AUTOSAR XML (schema 4-2-2)
package /ComponentTypes
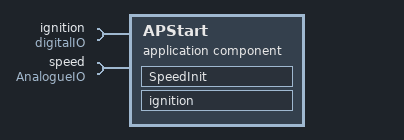
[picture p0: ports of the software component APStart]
  application sw component type APStart
    require port ignition: nonqueued-receiver-com-spec{data-element=boolean, init-value=0}, required-interface=digitalIO
    require port speed: nonqueued-receiver-com-spec{data-element=speed, init-value=0}, required-interface=AnalogueIO
    behavior APStart_InternalBehavior: data-type-mapping=speedMapSet
      init event SpeedPoll_InitEvent: start-on-event=SpeedInit
      init event ignition_InitEvent: start-on-event=ignition
      port-api-options:
        enable-take-address=true, error-handling=NO-TRANSFORMER-ERROR-HANDLING, indirect-api=true, port=ignition
        enable-take-address=true, error-handling=NO-TRANSFORMER-ERROR-HANDLING, indirect-api=true, port=speed
      runnable SpeedInit
        data-receive-point-by-arguments:
          access REC_speed_speed: accessed-variable=speed.speed
      runnable ignition
        data-receive-point-by-arguments:
          access REC_ignition_boolean: accessed-variable=ignition.boolean
  swc implementation APStart_Implementation: behavior=APStart_InternalBehavior
